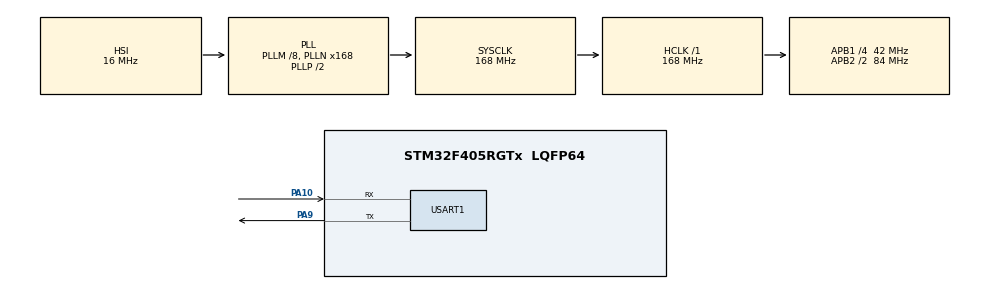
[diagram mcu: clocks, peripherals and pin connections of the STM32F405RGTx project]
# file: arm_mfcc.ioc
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Mcu.Family=STM32F4
Mcu.Name=STM32F405RGTx
Mcu.Package=LQFP64
NVIC.PriorityGroup=NVIC_PRIORITYGROUP_4
PA10.Mode=Asynchronous
PA10.Signal=USART1_RX
PA13.Mode=Serial_Wire
PA13.Signal=SYS_JTMS-SWDIO
PA14.Mode=Serial_Wire
PA14.Signal=SYS_JTCK-SWCLK
PA9.Mode=Asynchronous
PA9.Signal=USART1_TX
PH0-OSC_IN.Mode=HSE-External-Oscillator
PH0-OSC_IN.Signal=RCC_OSC_IN
PH1-OSC_OUT.Mode=HSE-External-Oscillator
PH1-OSC_OUT.Signal=RCC_OSC_OUT
ProjectManager.HeapSize=0x5000
ProjectManager.StackSize=0x800
ProjectManager.TargetToolchain=STM32CubeIDE
RCC.48MHZClocksFreq_Value=84000000
RCC.AHBFreq_Value=168000000
RCC.APB1CLKDivider=RCC_HCLK_DIV4
RCC.APB1Freq_Value=42000000
RCC.APB1TimFreq_Value=84000000
RCC.APB2CLKDivider=RCC_HCLK_DIV2
RCC.APB2Freq_Value=84000000
RCC.APB2TimFreq_Value=168000000
RCC.CortexFreq_Value=168000000
RCC.HCLKFreq_Value=168000000
RCC.HSE_VALUE=8000000
RCC.HSI_VALUE=16000000
RCC.LSE_VALUE=32768
RCC.PLLM=8
RCC.PLLN=168
RCC.SYSCLKFreq_VALUE=168000000
RCC.SYSCLKSource=RCC_SYSCLKSOURCE_PLLCLK
RCC.VCOOutputFreq_Value=336000000
STMicroelectronics.X-CUBE-AI.7.3.0.ActivationBufferSizeList=53424
STMicroelectronics.X-CUBE-AI.7.3.0.ActivationBuffers=pool0
STMicroelectronics.X-CUBE-AI.7.3.0.ActivationNames=pool0
STMicroelectronics.X-CUBE-AI.7.3.0.ActivationSizes=AI_KWS_NETWORK_DATA_ACTIVATION_1_SIZE
STMicroelectronics.X-CUBE-AI.7.3.0.ApplicationCcDeviceJjApplication=ApplicationTemplate
STMicroelectronics.X-CUBE-AI.7.3.0.HeapSize=0x5000
STMicroelectronics.X-CUBE-AI.7.3.0.InternalRamActivationBufferMaxSize=AI_KWS_NETWORK_DATA_ACTIVATIONS_SIZE
STMicroelectronics.X-CUBE-AI.7.3.0.LatestDirectoryUsed-ba8332e5eccde6ac9ddf017e4b1ed5b85bfabebd090dd0f974770ccc99056144=C\:\\Users\\13588\\Desktop\\cnn\\kws_arm_torch\\torch
STMicroelectronics.X-CUBE-AI.7.3.0.MaximumNumberOfInputLayer=1
STMicroelectronics.X-CUBE-AI.7.3.0.MaximumNumberOfOutputLayer=1
STMicroelectronics.X-CUBE-AI.7.3.0.MaximumSizeOfInputLayer=1
STMicroelectronics.X-CUBE-AI.7.3.0.MaximumSizeOfOutputLayer=1
STMicroelectronics.X-CUBE-AI.7.3.0.ModelActualCompression-ba8332e5eccde6ac9ddf017e4b1ed5b85bfabebd090dd0f974770ccc99056144=0.0
STMicroelectronics.X-CUBE-AI.7.3.0.ModelCompression-ba8332e5eccde6ac9ddf017e4b1ed5b85bfabebd090dd0f974770ccc99056144=None
STMicroelectronics.X-CUBE-AI.7.3.0.ModelFlashOccupation-ba8332e5eccde6ac9ddf017e4b1ed5b85bfabebd090dd0f974770ccc99056144=201396
STMicroelectronics.X-CUBE-AI.7.3.0.ModelHashList=ba8332e5eccde6ac9ddf017e4b1ed5b85bfabebd090dd0f974770ccc99056144
STMicroelectronics.X-CUBE-AI.7.3.0.ModelKind-ba8332e5eccde6ac9ddf017e4b1ed5b85bfabebd090dd0f974770ccc99056144=ONNX
STMicroelectronics.X-CUBE-AI.7.3.0.ModelMacc-ba8332e5eccde6ac9ddf017e4b1ed5b85bfabebd090dd0f974770ccc99056144=2650182
STMicroelectronics.X-CUBE-AI.7.3.0.ModelName-ba8332e5eccde6ac9ddf017e4b1ed5b85bfabebd090dd0f974770ccc99056144=kws_network
STMicroelectronics.X-CUBE-AI.7.3.0.ModelNameList=kws_network
STMicroelectronics.X-CUBE-AI.7.3.0.ModelRamOccupation-ba8332e5eccde6ac9ddf017e4b1ed5b85bfabebd090dd0f974770ccc99056144=53424
STMicroelectronics.X-CUBE-AI.7.3.0.ModelStructureFile-ba8332e5eccde6ac9ddf017e4b1ed5b85bfabebd090dd0f974770ccc99056144=C\:\\Users\\13588\\Desktop\\cnn\\kws_arm_torch\\torch\\best_model.onnx
STMicroelectronics.X-CUBE-AI.7.3.0.ModelType-ba8332e5eccde6ac9ddf017e4b1ed5b85bfabebd090dd0f974770ccc99056144=Saved model
STMicroelectronics.X-CUBE-AI.7.3.0.ReadyForCodeGeneration=true
STMicroelectronics.X-CUBE-AI.7.3.0.StackSize=0x800
STMicroelectronics.X-CUBE-AI.7.3.0.WorkingBufferStartAddrList=0xFFFFFFFF
STMicroelectronics.X-CUBE-AI.7.3.0.XAaCUBEAaAICcArtificialOoIntelligenceJjCore=true
STMicroelectronics.X-CUBE-AI.7.3.0.copyWeightToRam=false
STMicroelectronics.X-CUBE-AI.7.3.0.customLayerConfigEnabled=false
STMicroelectronics.X-CUBE-AI.7.3.0.useInputAllocation=true
STMicroelectronics.X-CUBE-AI.7.3.0.useOutputAllocation=true
STMicroelectronics.X-CUBE-ALGOBUILD.1.3.0.LibraryCcDSPOoLibraryJjDSPOoLibrary=true
USART1.VirtualMode=VM_ASYNC
VP_CRC_VS_CRC.Mode=CRC_Activate
VP_STMicroelectronics.X-CUBE-AI_VS_ArtificialOoIntelligenceJjXAaCUBEAaAI_7.3.0.Mode=ArtificialOoIntelligenceJjXAaCUBEAaAI
VP_STMicroelectronics.X-CUBE-AI_VS_DeviceJjApplication_7.3.0.Mode=DeviceJjApplication
VP_STMicroelectronics.X-CUBE-ALGOBUILD_VS_DSPOoLibraryJjLibrary_1.3.0_1.3.0.Mode=DSPOoLibraryJjLibrary
board=custom

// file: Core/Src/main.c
/* USER CODE BEGIN Header */
/**
  ******************************************************************************
  * @file           : main.c
  * @brief          : Main program body
  ******************************************************************************
  * @attention
  *
  * Copyright (c) 2023 STMicroelectronics.
  * All rights reserved.
  *
  * This software is licensed under terms that can be found in the LICENSE file
  * in the root directory of this software component.
  * If no LICENSE file comes with this software, it is provided AS-IS.
  *
  ******************************************************************************
  */
/* USER CODE END Header */
#include "main.h"
#include "crc.h"
#include "usart.h"
#include "gpio.h"
#include "app_x-cube-ai.h"

/* USER CODE BEGIN Includes */
#include "kws_mfcc.h"

#include "audio_one.h"
#include "audio_two.h"
#include "audio_three.h"
#include "audio_four.h"
#include "audio_five.h"
/* USER CODE END Includes */

void SystemClock_Config(void);

/* USER CODE BEGIN 0 */
float out_data[6];
void kws_audio_process(const int16_t * audio_data)
{
    float *ret_data;
    uint8_t max_index = 0;
    int32_t now = HAL_GetTick();
    ret_data = KWS_MFCC_compte(audio_data);
    kws_run(ret_data,out_data);
    int32_t end = HAL_GetTick();
    Debug("speed time:%d  ",end-now);

    for(int i =0;i<6;i++)
    {
     if(out_data[i]>out_data[max_index])
     {
    	 max_index = i;
     }
    }
    Debug("result is %d\r\n",max_index);
}
/* USER CODE END 0 */

int main(void)
{

  /* MCU Configuration--------------------------------------------------------*/

  /* Reset of all peripherals, Initializes the Flash interface and the Systick. */
  HAL_Init();

  /* Configure the system clock */
  SystemClock_Config();

  /* Initialize all configured peripherals */
  MX_GPIO_Init();
  MX_USART1_UART_Init();
  MX_CRC_Init();
  //MX_X_CUBE_AI_Init();
  /* USER CODE BEGIN 2 */
  kws_init();
  KWS_MFCC_init();

Debug("test 1->");
kws_audio_process(audio_one);
Debug("test 2->");
kws_audio_process(audio_two);
Debug("test 3->");
kws_audio_process(audio_three);
Debug("test 4->");
kws_audio_process(audio_four);
Debug("test 5->");
kws_audio_process(audio_five);

  /* USER CODE END 2 */

  /* Infinite loop */
  while (1)
  {

  //MX_X_CUBE_AI_Process();
  }
}

void SystemClock_Config(void)
{
  RCC_OscInitTypeDef RCC_OscInitStruct = {0};
  RCC_ClkInitTypeDef RCC_ClkInitStruct = {0};

  /** Configure the main internal regulator output voltage
  */
  __HAL_RCC_PWR_CLK_ENABLE();
  __HAL_PWR_VOLTAGESCALING_CONFIG(PWR_REGULATOR_VOLTAGE_SCALE1);

  /** Initializes the RCC Oscillators according to the specified parameters
  * in the RCC_OscInitTypeDef structure.
  */
  RCC_OscInitStruct.OscillatorType = RCC_OSCILLATORTYPE_HSI;
  RCC_OscInitStruct.HSIState = RCC_HSI_ON;
  RCC_OscInitStruct.HSICalibrationValue = RCC_HSICALIBRATION_DEFAULT;
  RCC_OscInitStruct.PLL.PLLState = RCC_PLL_ON;
  RCC_OscInitStruct.PLL.PLLSource = RCC_PLLSOURCE_HSI;
  RCC_OscInitStruct.PLL.PLLM = 8;
  RCC_OscInitStruct.PLL.PLLN = 168;
  RCC_OscInitStruct.PLL.PLLP = RCC_PLLP_DIV2;
  RCC_OscInitStruct.PLL.PLLQ = 4;
  if (HAL_RCC_OscConfig(&RCC_OscInitStruct) != HAL_OK)
  {
    Error_Handler();
  }

  /** Initializes the CPU, AHB and APB buses clocks
  */
  RCC_ClkInitStruct.ClockType = RCC_CLOCKTYPE_HCLK|RCC_CLOCKTYPE_SYSCLK
                              |RCC_CLOCKTYPE_PCLK1|RCC_CLOCKTYPE_PCLK2;
  RCC_ClkInitStruct.SYSCLKSource = RCC_SYSCLKSOURCE_PLLCLK;
  RCC_ClkInitStruct.AHBCLKDivider = RCC_SYSCLK_DIV1;
  RCC_ClkInitStruct.APB1CLKDivider = RCC_HCLK_DIV4;
  RCC_ClkInitStruct.APB2CLKDivider = RCC_HCLK_DIV2;

  if (HAL_RCC_ClockConfig(&RCC_ClkInitStruct, FLASH_LATENCY_5) != HAL_OK)
  {
    Error_Handler();
  }
}

void Error_Handler(void)
{
  __disable_irq();
  while (1)
  {
  }
}
